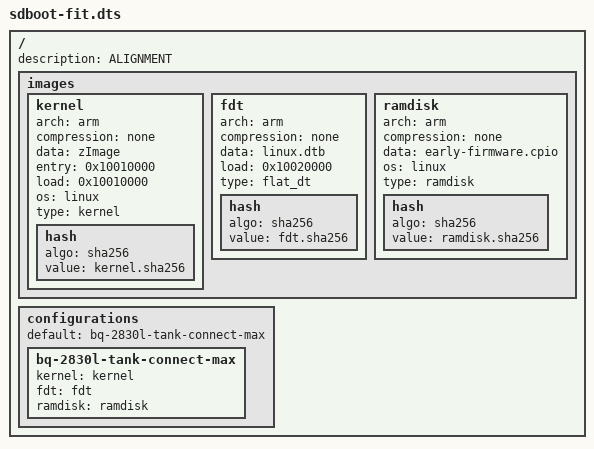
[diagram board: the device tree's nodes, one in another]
// SPDX-License-Identifier: GPL-2.0-only
/dts-v1/;
/ {
	description = "ALIGNMENT";
	images {
		kernel {
			arch = "arm";
			compression = "none";
			data = /incbin/("zImage");
			entry = <0x10010000>;
			load = <0x10010000>;
			os = "linux";
			type = "kernel";
			hash { algo = "sha256"; value = /incbin/("kernel.sha256"); };
		};
		fdt {
			arch = "arm";
			compression = "none";
			data = /incbin/("linux.dtb");
			load = <0x10020000>;
			type = "flat_dt";
			hash { algo = "sha256"; value = /incbin/("fdt.sha256"); };
		};
		ramdisk {
			arch = "arm";
			compression = "none";
			data = /incbin/("early-firmware.cpio");
			os = "linux";
			type = "ramdisk";
			hash { algo = "sha256"; value = /incbin/("ramdisk.sha256"); };
		};
	};
	configurations {
		default = "bq-2830l-tank-connect-max";
		bq-2830l-tank-connect-max { kernel = "kernel"; fdt = "fdt"; ramdisk = "ramdisk"; };
	};
};
